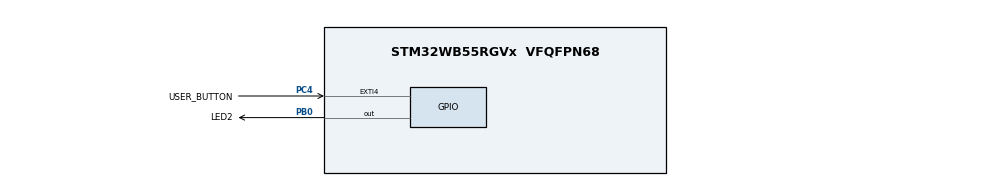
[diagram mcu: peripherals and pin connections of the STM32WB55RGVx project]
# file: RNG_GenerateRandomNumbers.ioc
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Mcu.Family=STM32WB
Mcu.Name=STM32WB55RGVx
Mcu.Package=VFQFPN68
NVIC.EXTI4_IRQn=true\:0\:0\:false\:false\:true\:true\:true
NVIC.PriorityGroup=NVIC_PRIORITYGROUP_4
PB0.GPIO_Label=LED2
PB0.GPIO_PuPd=GPIO_NOPULL
PB0.Signal=GPIO_Output
PC4.GPIO_Label=USER_BUTTON
PC4.GPIO_ModeDefaultEXTI=GPIO_MODE_IT_FALLING
PC4.GPIO_PuPd=GPIO_PULLUP
PC4.Signal=GPXTI4
ProjectManager.HeapSize=0x200
ProjectManager.StackSize=0x400
ProjectManager.TargetToolchain=EWARM V8
RCC.ADCFreq_Value=16000000
RCC.AHB2CLKDivider=RCC_SYSCLK_DIV2
RCC.AHBFreq_Value=16000000
RCC.APB1Freq_Value=16000000
RCC.APB1TimFreq_Value=16000000
RCC.APB2Freq_Value=16000000
RCC.APB2TimFreq_Value=16000000
RCC.APB3Freq_Value=16000000
RCC.CodegenConfigPeriph=false
RCC.CortexFreq_Value=16000000
RCC.HCLKFreq_Value=16000000
RCC.HSE_VALUE=8000000
RCC.HSI48_VALUE=48000000
RCC.HSI_VALUE=16000000
RCC.LSE_VALUE=32768
RCC.PLLN=32
RCC.SYSCLKFreq_VALUE=16000000
RCC.SYSCLKSource=RCC_SYSCLKSOURCE_HSI
RCC.USBFreq_Value=16000000
RCC.VCOOutputFreq_Value=128000000
VP_RNG_VS_RNG.Mode=RNG_Activate
board=custom

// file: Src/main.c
/* USER CODE BEGIN Header */
/**
  ******************************************************************************
  * @file    Examples_LL/RNG/RNG_GenerateRandomNumbers/Src/main.c
  * @author  MCD Application Team
  * @brief   This example describes how to use RNG peripheral for generating random
  *          numbers using the STM32WBxx RNG LL API.
  *          Peripheral initialization done using LL unitary services functions.
  ******************************************************************************
  * @attention
  *
  * <h2><center>&copy; Copyright (c) 2019 STMicroelectronics.
  * All rights reserved.</center></h2>
  *
  * This software component is licensed by ST under BSD 3-Clause license,
  * the "License"; You may not use this file except in compliance with the
  * License. You may obtain a copy of the License at:
  *                        opensource.org/licenses/BSD-3-Clause
  *
  ******************************************************************************
  */
/* USER CODE END Header */
#include "main.h"

/* USER CODE BEGIN PD */
#if (USE_TIMEOUT == 1)
#define RNG_GENERATION_TIMEOUT   20
#endif /* USE_TIMEOUT */

#define    NB_OF_GENERATED_RANDOM_NUMBERS      8       /* Nb of Random numbers generated after eash User button press */

/* USER CODE END PD */

/* USER CODE BEGIN PV */

#if (USE_TIMEOUT == 1)
uint32_t Timeout = 0; /* Variable used for Timeout management */
#endif /* USE_TIMEOUT */
__IO uint8_t ubButtonPress = 0;

/* Array used for storing generated Random 32bit Numbers */
__IO uint32_t aRandom32bit[NB_OF_GENERATED_RANDOM_NUMBERS];
/* USER CODE END PV */

void SystemClock_Config(void);
static void MX_GPIO_Init(void);
static void MX_RNG_Init(void);
/* USER CODE BEGIN PFP */

void     RandomNumbersGeneration(void);
void     LED_Init(void);
void     LED_On(void);
void     LED_Blinking(uint32_t Period);
void     UserButton_Init(void);
void     WaitForUserButtonPress(void);

/* USER CODE END PFP */

int main(void)
{

  /* MCU Configuration--------------------------------------------------------*/

  /* Reset of all peripherals, Initializes the Flash interface and the Systick. */

  NVIC_SetPriorityGrouping(NVIC_PRIORITYGROUP_4);

  /* System interrupt init*/

  /* Configure the system clock */
  SystemClock_Config();

  /* Initialize all configured peripherals */
  MX_GPIO_Init();
  MX_RNG_Init();
  /* USER CODE BEGIN 2 */

  /* Wait for User push-button (SW1) press to trigger random numbers generation */
  WaitForUserButtonPress();

  /* Generate Random Numbers series */
  RandomNumbersGeneration();
  /* USER CODE END 2 */

  /* Infinite loop */
  while (1)
  {

  }
}

void SystemClock_Config(void)
{
  /* HSI configuration and activation */
  LL_RCC_HSI_Enable();
  while(LL_RCC_HSI_IsReady() != 1)
  {
  }

  /* Sysclk activation on the HSI */
  /* Set CPU1 prescaler*/
  LL_RCC_SetAHBPrescaler(LL_RCC_SYSCLK_DIV_1);

  /* Set CPU2 prescaler*/
  LL_C2_RCC_SetAHBPrescaler(LL_RCC_SYSCLK_DIV_2);

  LL_RCC_SetSysClkSource(LL_RCC_SYS_CLKSOURCE_HSI);
  while(LL_RCC_GetSysClkSource() != LL_RCC_SYS_CLKSOURCE_STATUS_HSI)
  {
  }

  /* Set AHB SHARED prescaler*/
  LL_RCC_SetAHB4Prescaler(LL_RCC_SYSCLK_DIV_1);

  /* Set APB1 prescaler*/
  LL_RCC_SetAPB1Prescaler(LL_RCC_APB1_DIV_1);

  /* Set APB2 prescaler*/
  LL_RCC_SetAPB2Prescaler(LL_RCC_APB2_DIV_1);

  LL_Init1msTick(16000000);

  /* Update CMSIS variable (which can be updated also through SystemCoreClockUpdate function) */
  LL_SetSystemCoreClock(16000000);
}

static void MX_RNG_Init(void)
{

  /* Peripheral clock enable */
  LL_AHB3_GRP1_EnableClock(LL_AHB3_GRP1_PERIPH_RNG);

  /* USER CODE BEGIN RNG_Init 1 */

  /* Configure PLLSAI1 to enable 48M domain
    - Keep same PLLSAI1 source (HSI) and PLLM factor (DIV1) used for main PLL
    - Select PLLSAI1_N & PLLSAI1_Q to have a frequency of 48MHz
        * PLLSAI1_Q output = (((HSI Freq / PLLM) * PLLSAI1_N) / PLLSAI1_Q)
        *                  = (((16000000  /   1 ) *    6    ) /    2     ) */
  LL_RCC_PLLSAI1_ConfigDomain_48M(LL_RCC_PLLSOURCE_HSI, LL_RCC_PLLM_DIV_1, 6, LL_RCC_PLLSAI1Q_DIV_2);

  /* Enable PLLSAI1*/
  LL_RCC_PLLSAI1_Enable();
  /*  Enable PLLSAI1 output mapped on 48MHz domain clock */
  LL_RCC_PLLSAI1_EnableDomain_48M();
  /* Wait for PLLSAI1 ready flag */
  while(LL_RCC_PLLSAI1_IsReady() != 1)
  {
  }

  /*  Write the peripherals independent clock configuration register :
      choose PLLSAI1 source as the 48 MHz clock is needed for the RNG
      Linear Feedback Shift Register */
  LL_RCC_SetUSBClockSource(LL_RCC_USB_CLKSOURCE_PLLSAI1);
  LL_RCC_SetRNGClockSource(LL_RCC_RNG_CLKSOURCE_CLK48);
  /* USER CODE END RNG_Init 1 */
  LL_RNG_Enable(RNG);
  LL_RNG_EnableClkErrorDetect(RNG);

}

static void MX_GPIO_Init(void)
{
  LL_EXTI_InitTypeDef EXTI_InitStruct = {0};
  LL_GPIO_InitTypeDef GPIO_InitStruct = {0};

  /* GPIO Ports Clock Enable */
  LL_AHB2_GRP1_EnableClock(LL_AHB2_GRP1_PERIPH_GPIOC);
  LL_AHB2_GRP1_EnableClock(LL_AHB2_GRP1_PERIPH_GPIOB);

  /**/
  LL_GPIO_ResetOutputPin(LED2_GPIO_Port, LED2_Pin);

  /**/
  LL_SYSCFG_SetEXTISource(LL_SYSCFG_EXTI_PORTC, LL_SYSCFG_EXTI_LINE4);

  /**/
  EXTI_InitStruct.Line_0_31 = LL_EXTI_LINE_4;
  EXTI_InitStruct.Line_32_63 = LL_EXTI_LINE_NONE;
  EXTI_InitStruct.LineCommand = ENABLE;
  EXTI_InitStruct.Mode = LL_EXTI_MODE_IT;
  EXTI_InitStruct.Trigger = LL_EXTI_TRIGGER_FALLING;
  LL_EXTI_Init(&EXTI_InitStruct);

  /**/
  LL_GPIO_SetPinPull(USER_BUTTON_GPIO_Port, USER_BUTTON_Pin, LL_GPIO_PULL_UP);

  /**/
  LL_GPIO_SetPinMode(USER_BUTTON_GPIO_Port, USER_BUTTON_Pin, LL_GPIO_MODE_INPUT);

  /**/
  GPIO_InitStruct.Pin = LED2_Pin;
  GPIO_InitStruct.Mode = LL_GPIO_MODE_OUTPUT;
  GPIO_InitStruct.Speed = LL_GPIO_SPEED_FREQ_LOW;
  GPIO_InitStruct.OutputType = LL_GPIO_OUTPUT_PUSHPULL;
  GPIO_InitStruct.Pull = LL_GPIO_PULL_NO;
  LL_GPIO_Init(LED2_GPIO_Port, &GPIO_InitStruct);

  /* EXTI interrupt init*/
  NVIC_SetPriority(EXTI4_IRQn, NVIC_EncodePriority(NVIC_GetPriorityGrouping(),0, 0));
  NVIC_EnableIRQ(EXTI4_IRQn);

}

/* USER CODE BEGIN 4 */

/**
  * @brief  This function performs several random numbers generation.
  * @note   Generated random numbers are stored in global variable array, so that
  *         generated values could be observed by user by watching variable content
  *         in specific debugger window
  * @param  None
  * @retval None
  */
void RandomNumbersGeneration(void)
{
  register uint8_t index = 0;

  /* Initialize random numbers generation */
  LL_RNG_Enable(RNG);

  /* Generate Random 32bit Numbers */
  for(index = 0; index < NB_OF_GENERATED_RANDOM_NUMBERS; index++)
  {
#if (USE_TIMEOUT == 1)
    Timeout = RNG_GENERATION_TIMEOUT;
#endif /* USE_TIMEOUT */

    /* Wait for DRDY flag to be raised */
    while (!LL_RNG_IsActiveFlag_DRDY(RNG))
    {
#if (USE_TIMEOUT == 1)
      /* Check Systick counter flag to decrement the time-out value */
      if (LL_SYSTICK_IsActiveCounterFlag())
      {
        if(Timeout-- == 0)
        {
          /* Time-out occurred. Set LED to blinking mode */
          LED_Blinking(LED_BLINK_SLOW);
        }
      }
#endif /* USE_TIMEOUT */
    }

    /* Check if error occurs */
    if (   (LL_RNG_IsActiveFlag_CECS(RNG) )
        || (LL_RNG_IsActiveFlag_SECS(RNG))  )
    {
      /* Clock or Seed Error detected. Set LED to blinking mode (Error type)*/
      LED_Blinking(LED_BLINK_ERROR);
    }

    /* Otherwise, no error detected : Value of generated random number could be retrieved
       and stored in dedicated array */
    aRandom32bit[index] = LL_RNG_ReadRandData32(RNG);
  }

  /* Stop random numbers generation */
  LL_RNG_Disable(RNG);

  /* Values of Generated Random numbers are now available in aRandom32bit array.
     LED2 is turned on */
  LED_On();
}

/**
  * @brief  Turn-on LED2.
  * @param  None
  * @retval None
  */
void LED_On(void)
{
  /* Turn LED2 on */
  LL_GPIO_SetOutputPin(LED2_GPIO_Port, LED2_Pin);
}

/**
  * @brief  Set LED2 to Blinking mode for an infinite loop (toggle period based on value provided as input parameter).
  * @param  Period : Period of time (in ms) between each toggling of LED
  *   This parameter can be user defined values. Pre-defined values used in that example are :
  *     @arg LED_BLINK_FAST : Fast Blinking
  *     @arg LED_BLINK_SLOW : Slow Blinking
  *     @arg LED_BLINK_ERROR : Error specific Blinking
  * @retval None
  */
void LED_Blinking(uint32_t Period)
{
  /* Toggle LED2 in an infinite loop */
  while (1)
  {
    LL_GPIO_TogglePin(LED2_GPIO_Port, LED2_Pin);
    LL_mDelay(Period);
  }
}

/**
  * @brief  Wait for User push-button (SW1) press to start transfer.
  * @param  None
  * @retval None
  */
  /*  */
void WaitForUserButtonPress(void)
{
  while (ubButtonPress == 0)
  {
    LL_GPIO_TogglePin(LED2_GPIO_Port, LED2_Pin);
    LL_mDelay(LED_BLINK_FAST);
  }

  /* Turn LED2 off */
  LL_GPIO_ResetOutputPin(LED2_GPIO_Port, LED2_Pin);
}

/******************************************************************************/
/*   IRQ HANDLER TREATMENT Functions                                          */
/******************************************************************************/
/**
  * @brief  Function to manage User push-button (SW1)
  * @param  None
  * @retval None
  */
void UserButton_Callback(void)
{
  /* Update User push-button (SW1) variable : to be checked in waiting loop in main program */
  ubButtonPress = 1;
}

/* USER CODE END 4 */

void Error_Handler(void)
{
}

/************************ (C) COPYRIGHT STMicroelectronics *****END OF FILE****/
